# ecd5_target_db register map
Vendor: Texas Instruments
Address unit: 16 bits
Registers are 32-bit, access per field, reset 0x0 unless marked. A register's access mark holds for its fields unless they carry their own. Offsets are as the file gives them; [hi:lo] are bit positions; {n}, {i} and the like mark numbered series; 'fields as' and 'values as' point back to an identical list.

## DSS (part 4 of 5) — ipxact12_to_ccs_generated
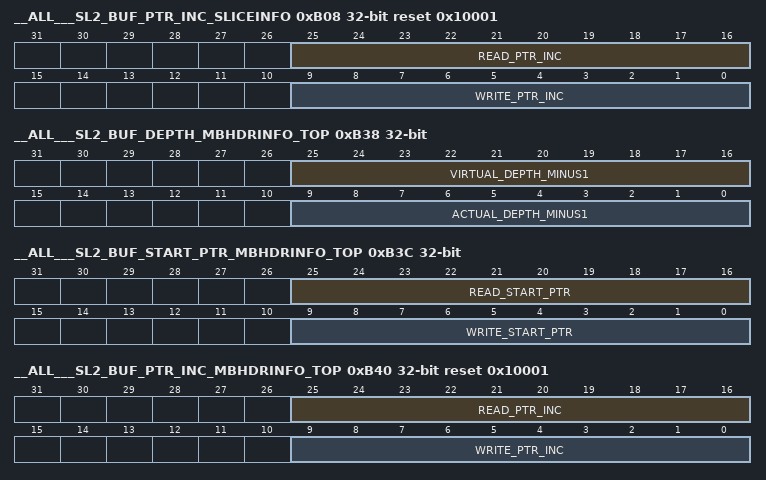
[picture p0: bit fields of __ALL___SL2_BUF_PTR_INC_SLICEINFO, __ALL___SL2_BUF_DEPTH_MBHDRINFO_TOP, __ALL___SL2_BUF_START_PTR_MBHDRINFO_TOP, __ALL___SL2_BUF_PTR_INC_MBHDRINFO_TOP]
0xB08 __ALL___SL2_BUF_PTR_INC_SLICEINFO reset 0x10001 — Buffer Control Pointer Increment Parameters for sliceInfo Note : 1. In decode, in CABAC N MB decoupled mode, this register defines the read and write pointer increment values for the sliceInfo SL2BC between FE and BE (input to BE from FE) 2. In decode, in frame decoupled mode and CAVLC mode, this register defines the write pointer increment value for the sliceInfo SL2BC between the BE and the ROP (output from BE to ROP) 3. In encode, this register defines the read and write pointer increment values for the sliceInfo SL2BC between ROP and BE (input to BE from ROP)
  [25:16] READ_PTR_INC rw — BC Increment value for read pointer
  [9:0] WRITE_PTR_INC rw — BC Increment value for Write pointer
0xB0C __ALL___SL2_BUF_DEPTH_MB — Buffer Control Parameters for MB virtual buffer between FE and BE Note : Valid only in CABAC N MB decoupled mode.
  [9:0] ACTUAL_DEPTH_MINUS1 rw — BC Actual Depth
{0xB18+8i} __ALL___SL2_BUF_DEPTH_BIN{i} (i=0..3) — Buffer Control Parameters for bin stream {i} Note : Valid only in N MB decoupled mode
  [15:0] ACTUAL_DEPTH_MINUS1 rw — BC Actual Depth
{0xB1C+8i} __ALL___SL2_BUF_START_PTR_BIN{i} (i=0..3) — Buffer Control Pointers for bit stream {i} Note : Valid only in N MB decoupled mode
  [9:0] READ_START_PTR rw — BC Start Value for Read Pointer
0xB38 __ALL___SL2_BUF_DEPTH_MBHDRINFO_TOP — Buffer Control Parameters for Top MBHdrInfo in decode, and Top/Bottom in Encode (both top and bottom MBHdrInfo go into the same buffer in encode)
  [25:16] VIRTUAL_DEPTH_MINUS1 rw — BC Virtual Depth
  [9:0] ACTUAL_DEPTH_MINUS1 rw — BC Actual Depth
0xB3C __ALL___SL2_BUF_START_PTR_MBHDRINFO_TOP — Buffer Control Pointers for Top MBHdrInfo in decode, and Top/Bottom in Encode (both top and bottom MBHdrInfo go into the same buffer in encode)
  [25:16] READ_START_PTR rw — BC Start Value for Read Pointer
  [9:0] WRITE_START_PTR rw — BC Start Value for Write Pointer
0xB40 __ALL___SL2_BUF_PTR_INC_MBHDRINFO_TOP reset 0x10001 — Buffer Control Pointer Increment Parameters for Top MBHdrInfo in decode, and Top/Bottom in Encode (both top and bottom MBHdrInfo go into the same buffer in encode)
  fields as __ALL___SL2_BUF_PTR_INC_SLICEINFO
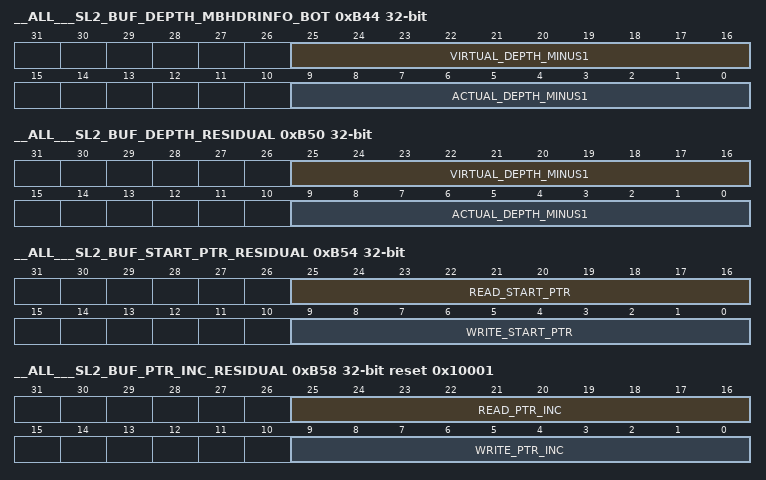
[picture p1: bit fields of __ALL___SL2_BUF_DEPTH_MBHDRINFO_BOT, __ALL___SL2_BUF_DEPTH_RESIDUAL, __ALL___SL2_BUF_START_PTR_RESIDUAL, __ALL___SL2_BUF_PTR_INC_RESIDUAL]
0xB44 __ALL___SL2_BUF_DEPTH_MBHDRINFO_BOT — Buffer Control Parameters for Bottom MBHdrInfo in decode Note : Unused in encode
  fields as __ALL___SL2_BUF_DEPTH_MBHDRINFO_TOP
0xB48 __ALL___SL2_BUF_START_PTR_MBHDRINFO_BOT — Buffer Control Pointers for Bottom MBHdrInfo in decode Note : Unused in encode
  [9:0] WRITE_START_PTR rw — BC Start Value for Write Pointer
0xB4C __ALL___SL2_BUF_PTR_INC_MBHDRINFO_BOT reset 0x1 — Buffer Control Pointer Increment Parameters for Bottom MBHdrInfo in decode Note : Unused in encode
  [9:0] WRITE_PTR_INC rw — BC Increment value for Write pointer
0xB50 __ALL___SL2_BUF_DEPTH_RESIDUAL — Buffer Control Parameters for Residual Data Note : Used in both encode and decode
  fields as __ALL___SL2_BUF_DEPTH_MBHDRINFO_TOP
0xB54 __ALL___SL2_BUF_START_PTR_RESIDUAL — Buffer Control Pointers for Residual Data Note : Used in both encode and decode
  fields as __ALL___SL2_BUF_START_PTR_MBHDRINFO_TOP
0xB58 __ALL___SL2_BUF_PTR_INC_RESIDUAL reset 0x10001 — Buffer Control Pointer Increment Parameters for Residual Data Note : Used in both encode and decode
  fields as __ALL___SL2_BUF_PTR_INC_SLICEINFO
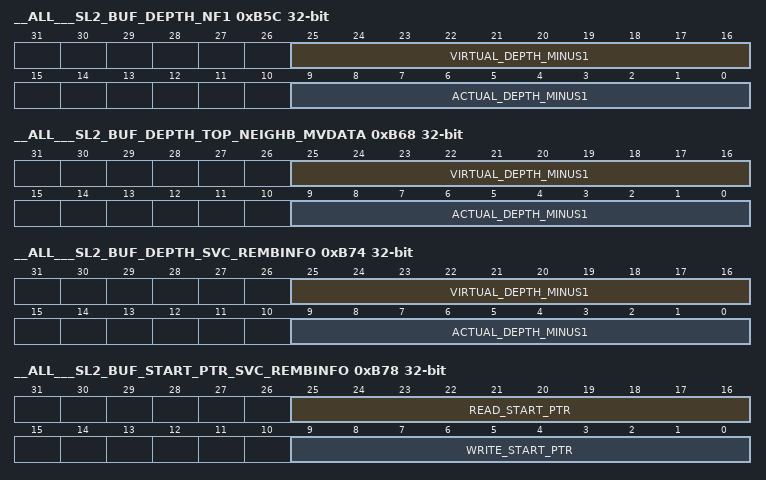
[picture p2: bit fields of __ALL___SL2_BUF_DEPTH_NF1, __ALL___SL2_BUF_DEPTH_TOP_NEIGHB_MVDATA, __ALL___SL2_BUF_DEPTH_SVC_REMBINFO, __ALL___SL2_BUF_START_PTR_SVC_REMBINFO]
0xB5C __ALL___SL2_BUF_DEPTH_NF1 — Buffer Control Parameters for NearNeighbourFlag (NF1) Note : Used in both encode and decode
  fields as __ALL___SL2_BUF_DEPTH_MBHDRINFO_TOP
0xB60 __ALL___SL2_BUF_START_PTR_NF1 — Buffer Control Pointers for NearNeighbourFlag (NF1) Note : Used in both encode and decode
  [9:0] WRITE_START_PTR rw — BC Start Value for Write Pointer
0xB64 __ALL___SL2_BUF_PTR_INC_NF1 reset 0x1 — Buffer Control Pointer Increment Parameters for NearNeighbourFlag (NF1) Note : Used in both encode and decode
  [9:0] WRITE_PTR_INC rw — BC Increment value for Write pointer
0xB68 __ALL___SL2_BUF_DEPTH_TOP_NEIGHB_MVDATA — Buffer Control Parameters for Top Neighbouring MB data to ME This is used only in encode
  fields as __ALL___SL2_BUF_DEPTH_MBHDRINFO_TOP
0xB6C __ALL___SL2_BUF_START_PTR_TOP_NEIGHB_MVDATA — Buffer Control Pointers for Top Neighbouring MB data to ME This is used only in encode
  [9:0] WRITE_START_PTR rw — BC Start Value for Write Pointer
0xB70 __ALL___SL2_BUF_PTR_INC_TOP_NEIGHB_MVDATA reset 0x1 — Buffer Control Pointer Increment Parameters for Top Neighbouring MB data to ME This is used only in encode
  [9:0] WRITE_PTR_INC rw — BC Increment value for Write pointer
0xB74 __ALL___SL2_BUF_DEPTH_SVC_REMBINFO — Buffer Control Parameters for SVC Reference Layer ECD MB Info
  fields as __ALL___SL2_BUF_DEPTH_MBHDRINFO_TOP
0xB78 __ALL___SL2_BUF_START_PTR_SVC_REMBINFO — Buffer Control Pointers for SVC Reference Layer ECD MB Info
  fields as __ALL___SL2_BUF_START_PTR_MBHDRINFO_TOP
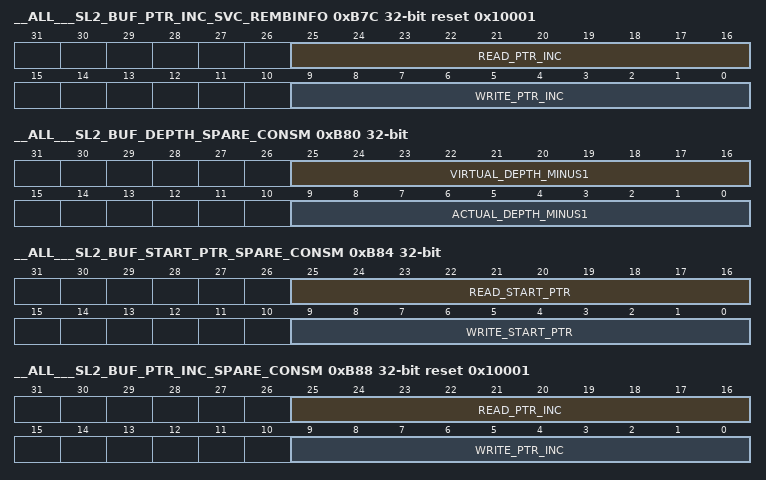
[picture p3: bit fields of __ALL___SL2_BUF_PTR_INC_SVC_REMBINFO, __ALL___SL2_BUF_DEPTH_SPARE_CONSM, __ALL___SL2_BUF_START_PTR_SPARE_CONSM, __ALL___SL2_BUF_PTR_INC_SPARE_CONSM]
0xB7C __ALL___SL2_BUF_PTR_INC_SVC_REMBINFO reset 0x10001 — Buffer Control Pointer Increment Parameters for SVC Reference Layer ECD MB Info
  fields as __ALL___SL2_BUF_PTR_INC_SLICEINFO
0xB80 __ALL___SL2_BUF_DEPTH_SPARE_CONSM — Buffer Control Parameters for Spare Consumer SL2BC
  fields as __ALL___SL2_BUF_DEPTH_MBHDRINFO_TOP
0xB84 __ALL___SL2_BUF_START_PTR_SPARE_CONSM — Buffer Control Pointers for Spare Consumer SL2BC
  fields as __ALL___SL2_BUF_START_PTR_MBHDRINFO_TOP
0xB88 __ALL___SL2_BUF_PTR_INC_SPARE_CONSM reset 0x10001 — Buffer Control Pointer Increment Parameters for Spare Consumer SL2BC
  fields as __ALL___SL2_BUF_PTR_INC_SLICEINFO
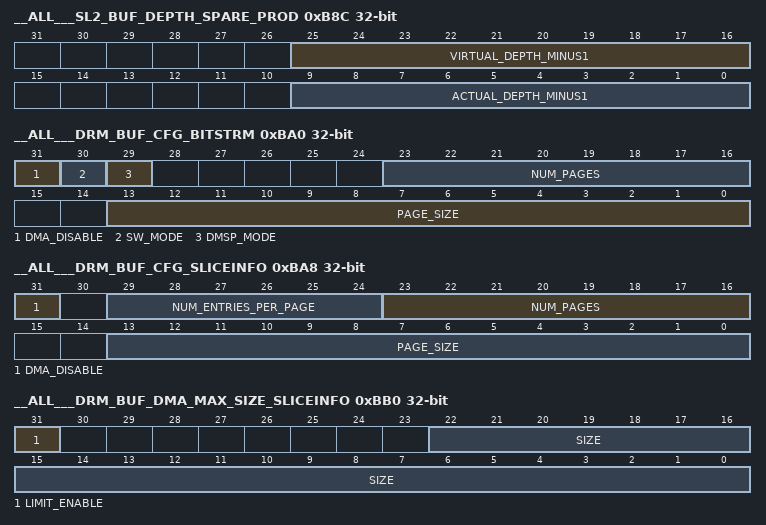
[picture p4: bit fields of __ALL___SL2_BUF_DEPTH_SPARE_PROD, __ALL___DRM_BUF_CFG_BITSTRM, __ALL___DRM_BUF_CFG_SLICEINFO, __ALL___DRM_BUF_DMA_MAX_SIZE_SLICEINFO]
0xB8C __ALL___SL2_BUF_DEPTH_SPARE_PROD — Buffer Control Parameters for Spare Producer SL2BC
  fields as __ALL___SL2_BUF_DEPTH_MBHDRINFO_TOP
0xB90 __ALL___SL2_BUF_START_PTR_SPARE_PROD — Buffer Control Pointers for Spare Producer SL2BC
  [9:0] WRITE_START_PTR rw — BC Start Value for Write Pointer
0xB94 __ALL___SL2_BUF_PTR_INC_SPARE_PROD reset 0x1 — Buffer Control Pointer Increment Parameters for Spare Priducer SL2BC
  [9:0] WRITE_PTR_INC rw — BC Increment value for Write pointer
0xBA0 __ALL___DRM_BUF_CFG_BITSTRM — Buffer parameters and configuration for bit stream Note : Unused in non-frame-decoupled configuration; the corresponding registers in FE_BUFFER_CONTROL are used.
  [31] DMA_DISABLE rw — If '1', disables the triggering of VDMA. Only the SL2 buffer management is activated.
  [30] SW_MODE rw — If '1', specifies SW interactive mode of operation. In this mode, the ECD5 does not interact directly with VDMA for bitstream DMA. Instead it triggers an interrupt for requesting DMA transfer of bitstream.
  [29] DMSP_MODE rw — If '1', specifies "Direct Multi-page SL2 population" mode of operation
  [23:16] NUM_PAGES rw — Number of pages in SL2
  [13:0] PAGE_SIZE rw — Size of each page in SL2 (in bytes); bits[3:0] are ignored, so the effective size is a multiple of 16 bytes
0xBA4 __ALL___DRM_BUF_DMAGROUPID_BITSTRM — DMA Group ID for bit stream Note : Unused in non-frame-decoupled configuration; the corresponding registers in FE_BUFFER_CONTROL are used.
  [5:0] ID rw — Group ID for VDMA transfer
0xBA8 __ALL___DRM_BUF_CFG_SLICEINFO — Buffer parameters and configuration for sliceInfo and sliceRPL Note : Used only in frame decoupled mode
  [31] DMA_DISABLE rw — If '1', disables the triggering of VDMA. Only the SL2 buffer management is activated.
  [29:24] NUM_ENTRIES_PER_PAGE rw — Number of data structure entries in each page of sliceInfo, sliceExpWeightTable and sliceRPL data. Note : This field (together w/ the size of each entry, i.e. for eg. sliceInfo size (2 words)) should be consistent with the PAGE_SIZE field, i.e. NUM_PAGE_ENTRIES * sizeof(sliceInfo) = DRM_BUF_CFG_SLICEINFO.PAGE_SIZE
  [23:16] NUM_PAGES rw — Number of pages of sliceInfo in SL2
  [13:0] PAGE_SIZE rw — Size of each page of sliceInfo in SL2 (in bytes); bits[3:0] are ignored, so the effective size is a multiple of 16 bytes This should be consistent w/ the value of DRM_BUF_CFG_SLICEINFO.NUM_ENTRIES_PER_PAGE, such that this number of sliceInfo entries should fit within the page size.
0xBAC __ALL___DRM_BUF_DMAGROUPID_SLICEINFO — DMA Group ID for sliceInfo and sliceRPL Note : Used only in frame decoupled mode
  [5:0] ID rw — Group ID for VDMA transfer
0xBB0 __ALL___DRM_BUF_DMA_MAX_SIZE_SLICEINFO — Max bytes DMA transfer limit for sliceRPL Note : Used only in frame decoupled mode
  [31] LIMIT_ENABLE rw — If '1', enables limiting the DMA transfer for bin stream 0 to "SIZE"
  [22:0] SIZE rw — Total maximum number of bytes that will be transferred by ECD through VDMA. The actual limit for transfer is "ceil( SIZE / DRM_BUF_CFG_SLICEINFO.PAGE_SIZE ) * PAGE_SIZE", i.e. the closest upper integral number of pages. This value will be decremented by HW when DRM is operational and should not be overwritten except when DRM is in IDLE.
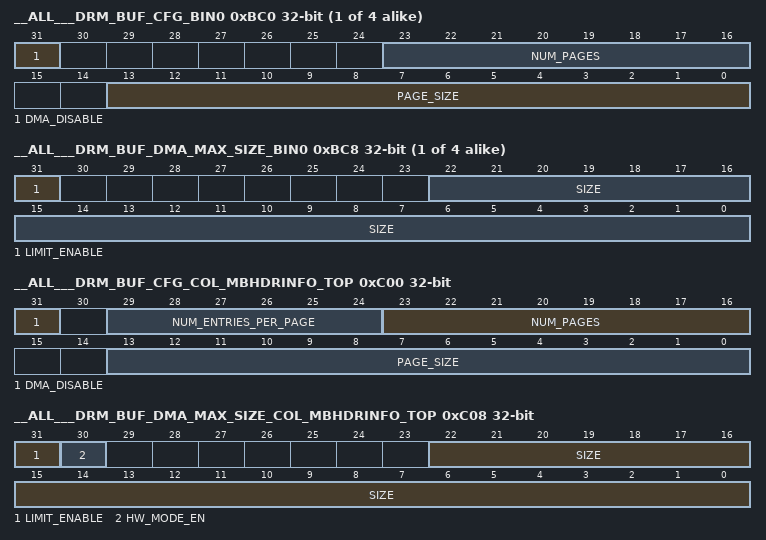
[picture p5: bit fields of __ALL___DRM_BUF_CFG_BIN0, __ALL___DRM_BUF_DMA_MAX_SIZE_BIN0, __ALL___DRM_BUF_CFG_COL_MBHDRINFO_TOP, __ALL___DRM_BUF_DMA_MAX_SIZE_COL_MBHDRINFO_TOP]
{0xBC0+0x10*i} __ALL___DRM_BUF_CFG_BIN{i} (i=0..3) — Buffer parameters and configuration for bin stream {i} Note : Used only in frame decoupled mode
  [31] DMA_DISABLE rw — If '1', disables the triggering of VDMA. Only the SL2 buffer management is activated.
  [23:16] NUM_PAGES rw — Number of pages in SL2
  [13:0] PAGE_SIZE rw — Size of each page in SL2 (in bytes); bits[3:0] are ignored, so the effective size is a multiple of 16 bytes
{0xBC4+0x10*i} __ALL___DRM_BUF_DMAGROUPID_BIN{i} (i=0..3) — DMA Group ID for bin stream {i} Note : Used only in frame decoupled mode
  [5:0] ID rw — Group ID for VDMA transfer
{0xBC8+0x10*i} __ALL___DRM_BUF_DMA_MAX_SIZE_BIN{i} (i=0..3) — Max bytes DMA transfer limit for bin stream {i} Note : Used only in frame decoupled mode
  [31] LIMIT_ENABLE rw — If '1', enables limiting the DMA transfer for bin stream 0 to "SIZE"
  [22:0] SIZE rw — Total maximum number of bytes that will be transferred by ECD through VDMA. The actual limit for transfer is "ceil( SIZE / DRM_BUF_CFG_BIN{i}.PAGE_SIZE ) * PAGE_SIZE", i.e. the closest upper integral number of pages. This value will be decremented by HW when DRM is operational and should not be overwritten except when DRM is in IDLE.
0xC00 __ALL___DRM_BUF_CFG_COL_MBHDRINFO_TOP — Buffer parameters and configuration for colocated Top MBHdrInfo
  [31] DMA_DISABLE rw — If '1', disables the triggering of VDMA. Only the SL2 buffer management is activated.
  [29:24] NUM_ENTRIES_PER_PAGE rw — Number of data structure entries in each page Note : This field (together w/ the size of each entry) should be consistent with the PAGE_SIZE field
  [23:16] NUM_PAGES rw — Number of pages in SL2
  [13:0] PAGE_SIZE rw — Size of each page in SL2 (in bytes); bits[3:0] are ignored, so the effective size is a multiple of 16 bytes Note : Can be left unused since deterministic transfer
0xC04 __ALL___DRM_BUF_DMAGROUPID_COL_MBHDRINFO_TOP — DMA Group ID for colocated Top MBHdrInfo
  [5:0] ID rw — Group ID for VDMA transfer
0xC08 __ALL___DRM_BUF_DMA_MAX_SIZE_COL_MBHDRINFO_TOP — Max bytes DMA transfer limit for colocated Top MBHdrInfo
  [31] LIMIT_ENABLE rw — If '1', enables limiting the DMA transfer for bin stream 0 to "SIZE"
  [30] HW_MODE_EN rw — If "1" enables programmation of the "SIZE" field through H/W interface
  [22:0] SIZE rw — Total maximum number of bytes that will be transferred by ECD through VDMA. The actual limit for transfer is "ceil( SIZE / DRM_BUF_CFG_COL_MBHDRINFO_TOP.PAGE_SIZE ) * PAGE_SIZE", i.e. the closest upper integral number of pages. This value will be decremented by HW when DRM is operational and should not be overwritten except when DRM is in IDLE.
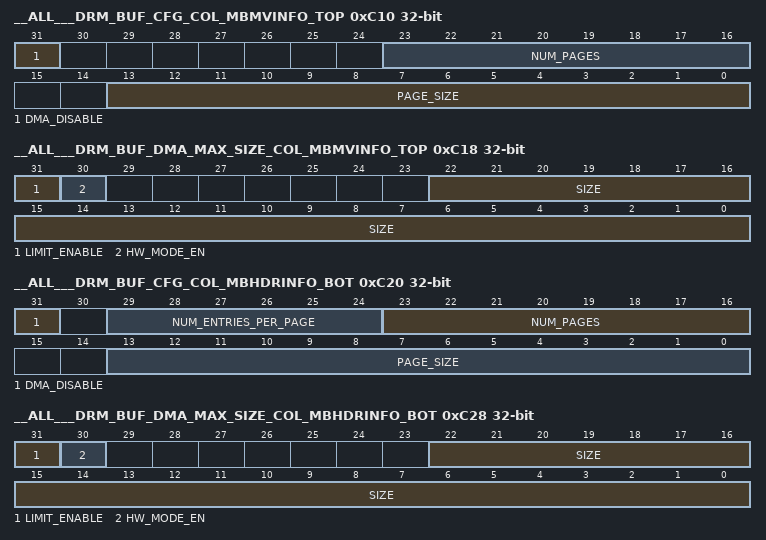
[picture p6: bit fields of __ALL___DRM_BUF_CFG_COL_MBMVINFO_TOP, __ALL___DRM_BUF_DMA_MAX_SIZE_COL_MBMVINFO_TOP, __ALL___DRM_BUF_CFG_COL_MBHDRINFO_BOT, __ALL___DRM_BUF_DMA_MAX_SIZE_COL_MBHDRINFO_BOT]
0xC10 __ALL___DRM_BUF_CFG_COL_MBMVINFO_TOP — Buffer parameters and configuration for colocated Top MBMVInfo
  fields as __ALL___DRM_BUF_CFG_BIN0
0xC14 __ALL___DRM_BUF_DMAGROUPID_COL_MBMVINFO_TOP — DMA Group ID for colocated Top MBMVInfo
  [5:0] ID rw — Group ID for VDMA transfer
0xC18 __ALL___DRM_BUF_DMA_MAX_SIZE_COL_MBMVINFO_TOP — Max bytes DMA transfer limit for colocated Top MBMVInfo
  [31] LIMIT_ENABLE rw — If '1', enables limiting the DMA transfer for bin stream 0 to "SIZE"
  [30] HW_MODE_EN rw — If "1" enables programmation of the "SIZE" field through H/W interface
  [22:0] SIZE rw — Total maximum number of bytes that will be transferred by ECD through VDMA. The actual limit for transfer is "ceil( SIZE / DRM_BUF_CFG_COL_MBMVINFO_TOP.PAGE_SIZE ) * PAGE_SIZE", i.e. the closest upper integral number of pages. This value will be decremented by HW when DRM is operational and should not be overwritten except when DRM is in IDLE.
0xC20 __ALL___DRM_BUF_CFG_COL_MBHDRINFO_BOT — Buffer parameters and configuration for colocated Bottom MBHdrInfo
  [31] DMA_DISABLE rw — If '1', disables the triggering of VDMA. Only the SL2 buffer management is activated.
  [29:24] NUM_ENTRIES_PER_PAGE rw — Number of data structure entries in each page Note : This field (together w/ the size of each entry) should be consistent with the PAGE_SIZE field
  [23:16] NUM_PAGES rw — Number of pages in SL2
  [13:0] PAGE_SIZE rw — Size of each page in SL2 (in bytes); bits[3:0] are ignored, so the effective size is a multiple of 16 bytes
0xC24 __ALL___DRM_BUF_DMAGROUPID_COL_MBHDRINFO_BOT — DMA Group ID for colocated Bottom MBHdrInfo
  [5:0] ID rw — Group ID for VDMA transfer
0xC28 __ALL___DRM_BUF_DMA_MAX_SIZE_COL_MBHDRINFO_BOT — Max bytes DMA transfer limit for colocated Bottom MBHdrInfo
  [31] LIMIT_ENABLE rw — If '1', enables limiting the DMA transfer for bin stream 0 to "SIZE"
  [30] HW_MODE_EN rw — If "1" enables programmation of the "SIZE" field through H/W interface
  [22:0] SIZE rw — Total maximum number of bytes that will be transferred by ECD through VDMA. The actual limit for transfer is "ceil( SIZE / DRM_BUF_CFG_COL_MBHDRINFO_BOT.PAGE_SIZE ) * PAGE_SIZE", i.e. the closest upper integral number of pages. This value will be decremented by HW when DRM is operational and should not be overwritten except when DRM is in IDLE.
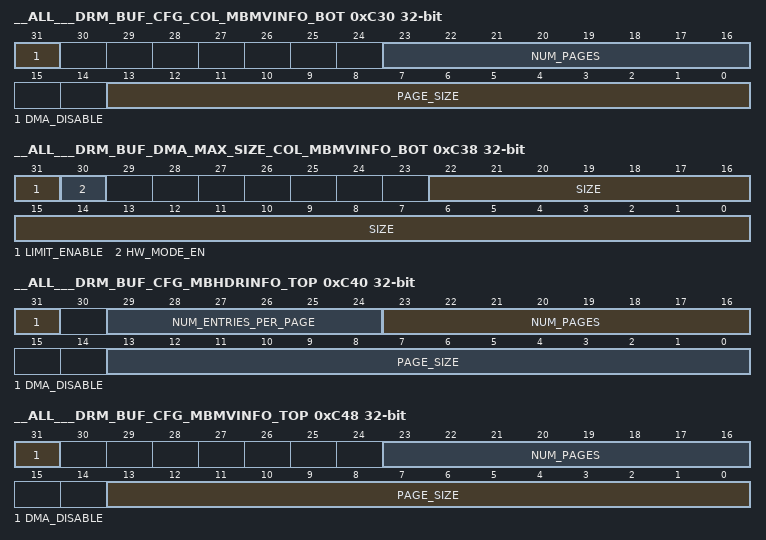
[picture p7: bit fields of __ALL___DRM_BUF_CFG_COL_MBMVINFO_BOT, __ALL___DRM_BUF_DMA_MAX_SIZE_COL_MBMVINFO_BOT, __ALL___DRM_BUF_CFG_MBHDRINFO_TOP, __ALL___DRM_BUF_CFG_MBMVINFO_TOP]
0xC30 __ALL___DRM_BUF_CFG_COL_MBMVINFO_BOT — Buffer parameters and configuration for colocated Bottom MBMVInfo
  fields as __ALL___DRM_BUF_CFG_BIN0
0xC34 __ALL___DRM_BUF_DMAGROUPID_COL_MBMVINFO_BOT — DMA Group ID for colocated Bottom MBMVInfo
  [5:0] ID rw — Group ID for VDMA transfer
0xC38 __ALL___DRM_BUF_DMA_MAX_SIZE_COL_MBMVINFO_BOT — Max bytes DMA transfer limit for colocated Bottom MBMVInfo
  [31] LIMIT_ENABLE rw — If '1', enables limiting the DMA transfer for bin stream 0 to "SIZE"
  [30] HW_MODE_EN rw — If "1" enables programmation of the "SIZE" field through H/W interface
  [22:0] SIZE rw — Total maximum number of bytes that will be transferred by ECD through VDMA. The actual limit for transfer is "ceil( SIZE / DRM_BUF_CFG_COL_MBMVINFO_BOT.PAGE_SIZE ) * PAGE_SIZE", i.e. the closest upper integral number of pages. This value will be decremented by HW when DRM is operational and should not be overwritten except when DRM is in IDLE.
0xC40 __ALL___DRM_BUF_CFG_MBHDRINFO_TOP — Buffer parameters and configuration for current Top MBHdrInfo
  fields as __ALL___DRM_BUF_CFG_COL_MBHDRINFO_BOT
0xC44 __ALL___DRM_BUF_DMAGROUPID_MBHDRINFO_TOP — DMA Group ID for current Top MBHdrInfo
  [5:0] ID rw — Group ID for VDMA transfer
0xC48 __ALL___DRM_BUF_CFG_MBMVINFO_TOP — Buffer parameters and configuration for current Top MBMVInfo
  fields as __ALL___DRM_BUF_CFG_BIN0
0xC4C __ALL___DRM_BUF_DMAGROUPID_MBMVINFO_TOP — DMA Group ID for current Top MBMVInfo
  [5:0] ID rw — Group ID for VDMA transfer
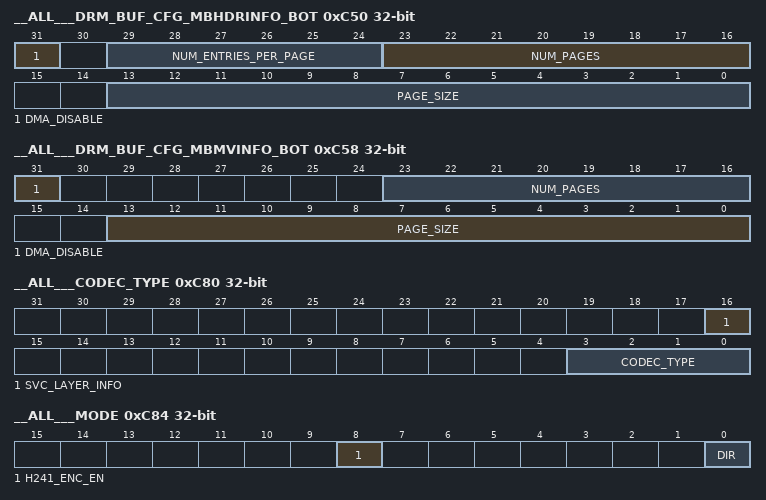
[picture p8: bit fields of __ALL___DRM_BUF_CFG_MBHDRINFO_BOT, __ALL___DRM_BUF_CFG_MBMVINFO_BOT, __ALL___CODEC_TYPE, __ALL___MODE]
0xC50 __ALL___DRM_BUF_CFG_MBHDRINFO_BOT — Buffer parameters and configuration for current Bottom MBHdrInfo
  fields as __ALL___DRM_BUF_CFG_COL_MBHDRINFO_BOT
0xC54 __ALL___DRM_BUF_DMAGROUPID_MBHDRINFO_BOT — DMA Group ID for current Bottom MBHdrInfo
  [5:0] ID rw — Group ID for VDMA transfer
0xC58 __ALL___DRM_BUF_CFG_MBMVINFO_BOT — Buffer parameters and configuration for current Bottom MBMVInfo
  fields as __ALL___DRM_BUF_CFG_BIN0
0xC5C __ALL___DRM_BUF_DMAGROUPID_MBMVINFO_BOT — DMA Group ID for current Bottom MBMVInfo
  [5:0] ID rw — Group ID for VDMA transfer
0xC80 __ALL___CODEC_TYPE — Codec Type
  [16] SVC_LAYER_INFO rw — Specifies whether current layer is base or enhancement layer; valid only id CODEC_TYPE == 1 (SVC) 0 - Base Layer 1 - Enhancement Layer
  [3:0] CODEC_TYPE rw — 0=>H.264, 1=>SVC, 2=>VP8
0xC84 __ALL___MODE — BE Mode
  [8] H241_ENC_EN rw — Specifies if Encoder is in H.241 mode 0 - H.241 Mode disabled 1 - H.241 Mode enabled
  [0] DIR rw — Specifies if encode or decode for BE 0 - Decode 1 - Encode Note : If DIR == 1 and ENTROPY_CODING_MODE == 1, note that FE0 shall not be enabled (since CABAC engine 0 will be used in encode mode)
0xC90 __ALL___DEC_CABAC_FRM_CFG ro — Frame Level Config for CABAC in decode
0xC94 __ALL___DEC_CABAC_L0_CFG ro — CABAC Basic (Level 0) Config for decode
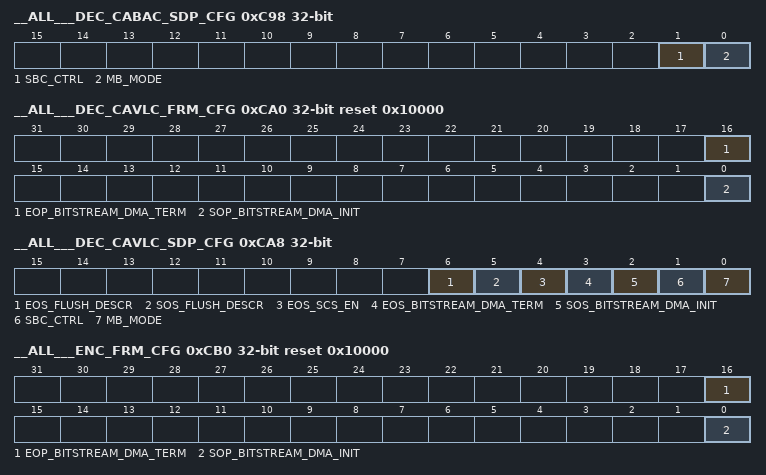
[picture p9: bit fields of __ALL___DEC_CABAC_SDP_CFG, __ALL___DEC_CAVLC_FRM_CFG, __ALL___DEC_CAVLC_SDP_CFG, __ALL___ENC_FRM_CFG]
0xC98 __ALL___DEC_CABAC_SDP_CFG — CABAC Slice Data Decode Configuration register
  [1] SBC_CTRL rw — Specifies the bin SBC control mode 0 - Initialize and Flush SBC at beginning and end of pipe respectively 1 - Initialize and Flush SBC at beginning and end of every MB respectively
  [0] MB_MODE rw — Specifies if MB mode is enabled for slice data decode 0 - No control at MB level 1 - MB processing engine has to be specifically enabled at every MB
0xCA0 __ALL___DEC_CAVLC_FRM_CFG reset 0x10000 — Frame Level Config for CAVLC in decode
  [16] EOP_BITSTREAM_DMA_TERM rw — Specifies if bit-stream DMA needs to be terminated at the end of pipe 0 - Do not terminate bit stream DMA at the end of pipe 1 - Terminate bitstream DMA at end of pipe
  [0] SOP_BITSTREAM_DMA_INIT rw — Specifies if bit-stream DMA needs to be initialized at the start of pipe (frame/sub-frame) 0 - Disable 1 - Enable
0xCA4 __ALL___DEC_CAVLC_L0_CFG ro — CAVLC Basic (Level 0) Config for decode
0xCA8 __ALL___DEC_CAVLC_SDP_CFG — CAVLC Decode Slice Data Processing Configuration
  [6] EOS_FLUSH_DESCR rw — Enable/Disable flush of current bitstream descriptor at end of slice 0 - Disable 1 - Enable
  [5] SOS_FLUSH_DESCR rw — Enable/Disable flush of current bitstream descriptor at start of slice 0 - Disable 1 - Enable
  [4] EOS_SCS_EN rw — Enable/Disable automatic startcode search on detecting end of slice 0 - Disable 1 - Enable
  [3] EOS_BITSTREAM_DMA_TERM rw — Specifies if bit-stream DMA needs to be terminated at the end of slice 0 - Do not terminate bit stream DMA at the end of slice 1 - Terminate bitstream DMA at end of slice
  [2] SOS_BITSTREAM_DMA_INIT rw — Specifies if bit-stream DMA need to be init at beginning of slice data processing 0 - Do not trigger initial bit stream DMA at the beginning of slice 1 - Trigger bitstream DMA at beginning of every slice
  [1] SBC_CTRL rw — Specifies the SBC control mode 0 - Initialize and Flush SBC at beginning and end of slice respectively 1 - Initialize and Flush SBC at beginning and end of every MB respectively Note : If SDP_EOS_SCS_EN == 1, then this bit will take effect for SBC close after the startcode search after EOS.
  [0] MB_MODE rw — Specifies if MB mode is enabled for slice data decode 0 - No control at MB level 1 - MB processing engine has to be specifically enabled at every MB
0xCB0 __ALL___ENC_FRM_CFG reset 0x10000 — Encoder Frame Level Initialization Configuration
  [16] EOP_BITSTREAM_DMA_TERM rw — Specifies if bit-stream DMA needs to be terminated at the end of pipe 0 - Do not terminate bit stream DMA at the end of pipe 1 - Terminate bitstream DMA at end of pipe Setting this bit results in flushing any un-transferred bit-stream data in the SL2 to DDR at the end of pipe, and discarding of bit-stream descriptors.
  [0] SOP_BITSTREAM_DMA_INIT rw — Specifies if bit-stream DMA needs to be initialized at the start of pipe (frame/sub-frame) 0 - Disable 1 - Enable
0xCB4 __ALL___ENC_L0_CFG ro — Encoder Basic (Level 0) Configuration
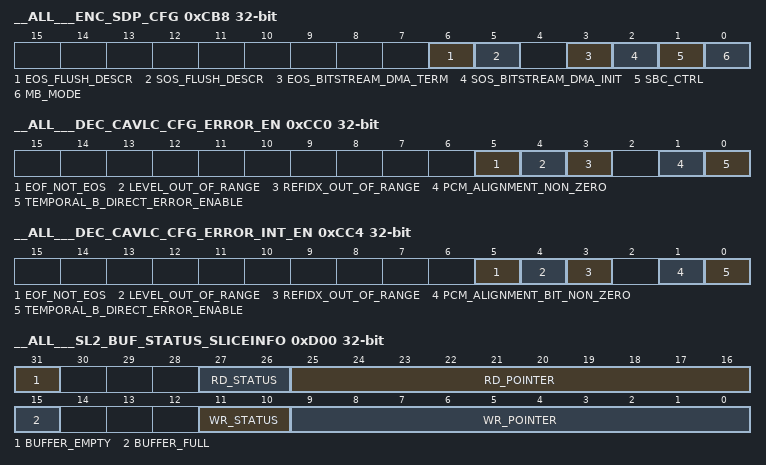
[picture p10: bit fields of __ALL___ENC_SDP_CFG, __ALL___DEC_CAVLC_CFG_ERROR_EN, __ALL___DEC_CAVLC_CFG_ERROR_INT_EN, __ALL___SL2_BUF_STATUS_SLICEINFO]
0xCB8 __ALL___ENC_SDP_CFG — Encoder Slice Processing Configuration
  [6] EOS_FLUSH_DESCR rw — Enable/Disable flush of current bitstream descriptor at end of slice 0 - Disable 1 - Enable
  [5] SOS_FLUSH_DESCR rw — Enable/Disable flush of current bitstream descriptor at start of slice 0 - Disable 1 - Enable
  [3] EOS_BITSTREAM_DMA_TERM rw — Specifies if bit-stream DMA needs to be terminated at the end of slice 0 - Do not terminate bit stream DMA at the end of slice 1 - Terminate bitstream DMA at end of slice Setting this bit results in flushing any un-transferred bit-stream data in the SL2 to DDR at the end of slice, and discarding of the bit-stream descriptors
  [2] SOS_BITSTREAM_DMA_INIT rw — Specifies if bit-stream DMA need to be init at beginning of slice data processing 0 - Do not initialize bit stream DMA at the beginning of slice 1 - Initialize bitstream DMA at beginning of every slice
  [1] SBC_CTRL rw — Specifies the SBC control mode 0 - Initialize and Flush SBC at beginning and end of slice respectively 1 - Initialize and Flush SBC at beginning and end of every MB respectively
  [0] MB_MODE rw — Specifies if MB mode is enabled for slice data decode 0 - No control at MB level 1 - MB processing engine has to be specifically enabled at every MB
0xCC0 __ALL___DEC_CAVLC_CFG_ERROR_EN — CAVLC Configuration register for enabling error for potentially incorrect behavior
  [5] EOF_NOT_EOS rw — If this value is 1 and EOS is not detected while decoding the last MB in the frame, error is flagged immediately.
  [4] LEVEL_OUT_OF_RANGE rw — If this value is 1 and level becomes out of range [-2^(7+bitDepth), 2^(7+bitDepth)-1] (due to error in level_suffix), error is flagged immediately.
  [3] REFIDX_OUT_OF_RANGE rw — If this value is 1 and ref_idx_lx ( x == 0 or 1 ) is out of the range [0,DEC_CAVLC_REF_IDX_MAX_Lx.VALUE], error is flagged immediately .
  [1] PCM_ALIGNMENT_NON_ZERO rw — If this value is 1 and pcm_alignment_zero_bit is not "0", error is flagged immediately.
  [0] TEMPORAL_B_DIRECT_ERROR_ENABLE rw — If this value is 1 and Temporal B Direct MB is detected, error is flagged immediately.
0xCC4 __ALL___DEC_CAVLC_CFG_ERROR_INT_EN — CAVLC Configuration register for enabling interrupt for potential incorrect behavior If a bit is set in this register and corresponding bit is not set in the DEC_CAVLC_CFG_ERROR_EN register, then, on hitting the corresponding condition in an MB, INT_ERR0 is triggered on the completion of the MB. CAVLC_DEC_ERR status bit is set in the interrupt status registers corresponding to INT_ERR0.
  [5] EOF_NOT_EOS rw — If this value is 1 and EOS is not detected while decoding the last MB in the frame, interrupt is (conditionally) generated on completion of MB.
  [4] LEVEL_OUT_OF_RANGE rw — If this value is 1 and level becomes out of range [-2^(7+bitDepth), 2^(7+bitDepth)-1] (due to error in level_suffix), interrupt is (conditionally) generated on completion of MB.
  [3] REFIDX_OUT_OF_RANGE rw — If this value is 1 and ref_idx_lx ( x == 0 or 1 ) is out of the range [0,DEC_CAVLC_REF_IDX_MAX_Lx.VALUE], interrupt is (conditionally) generated on completion of MB.
  [1] PCM_ALIGNMENT_BIT_NON_ZERO rw — If this value is 1 and pcm_alignment_zero_bit is not "0", interrupt is (conditionally) generated on completion of MB.
  [0] TEMPORAL_B_DIRECT_ERROR_ENABLE rw — If this value is 1 and Temporal B Direct MB is detected, interrupt is (conditionally) generated on completion of MB.
0xCC8 __ALL___DEC_CAVLC_REF_IDX_MAX_L0 — CAVLC Max refidx for L0
  [4:0] VALUE rw — Specifies the max refidx value for L0 for error checking
0xCCC __ALL___DEC_CAVLC_REF_IDX_MAX_L1 — CAVLC Max refidx for L1
  [4:0] VALUE rw — Specifies the max refidx value for L1 for error checking
0xCE4 __ALL___BE_MVINFO_TOP_DDR_OFFSET ro (reset mask 0xFF800000) — Start offset for MVInfo top buffer in DDR. Valid only in decode.
0xCE8 __ALL___BE_MVINFO_BOT_DDR_OFFSET ro (reset mask 0xFF800000) — Start offset for MVInfo bottom buffer in DDR. Valid only in decode.
0xD00 __ALL___SL2_BUF_STATUS_SLICEINFO ro — Buffer status for sliceInfo buffer (read/written) by BE Note : 1. Decode - CAVLC mode : this register reflects the status of the sliceInfo buffer between the BE and the ROP (output from BE to ROP). Although the SL2 buffer is not populated by the BE, the BE communicates the availability of data in the buffer to the ROP through SL2BC 2. Decode - CABAC N MB decoupled mode : this register reflects the status for the sliceInfo SL2BC between FE and BE (input to BE from FE) 3. Decode - CABAC frame decoupled mode : this register reflects the status of the sliceInfo buffer between the BE and the ROP (output from BE to ROP) 3. Encode : this register reflects the status for the sliceInfo SL2BC between ROP and BE (input to BE from ROP)
  [31] BUFFER_EMPTY — Buffer Empty Status 0 : Buffer Not Empty 1 : Buffer Empty Valid only in encode and non-frame decoupled CABAC decode
  [27:26] RD_STATUS — Indicates the BC status on the read side BC NOT READY = 00 (rd_core_busy=0 AND rd_bc_ready=0) BC READY = 01 (rd_core_busy=0 AND rd_bc_ready=1) BC BUSY = 1x (rd_core_busy=1) Valid only in encode and non-frame decoupled CABAC decode
  [25:16] RD_POINTER — Current Read Pointer Valid only in encode and non-frame decoupled CABAC decode
  [15] BUFFER_FULL — Buffer Full Status 0 : Buffer Not Full 1 : Buffer Full Valid only in encode and non-frame decoupled CABAC decode
  [11:10] WR_STATUS — Indicates the BC status on the write side BC NOT READY = 00 (wr_core_busy=0 AND wr_bc_ready=0) BC READY = 01 (wr_core_busy=0 AND wr_bc_ready=1) BC BUSY = 1x (wr_core_busy=1)
  [9:0] WR_POINTER — Current Write Pointer
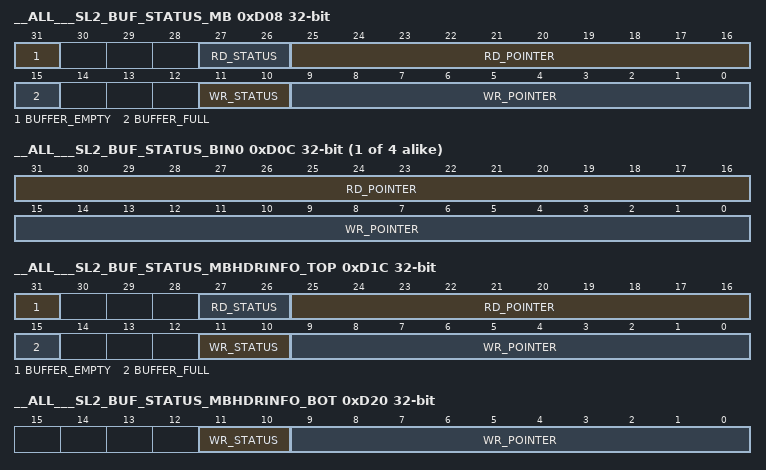
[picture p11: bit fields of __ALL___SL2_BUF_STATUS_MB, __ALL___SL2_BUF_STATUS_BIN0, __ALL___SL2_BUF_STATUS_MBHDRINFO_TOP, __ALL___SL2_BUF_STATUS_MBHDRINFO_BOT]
0xD08 __ALL___SL2_BUF_STATUS_MB ro — Buffer Status for MB virtual buffer between FE and BE Note : Valid only in CABAC decode in N MB decoupled mode
  [31] BUFFER_EMPTY — Buffer Empty Status 0 : Buffer Not Empty 1 : Buffer Empty
  [27:26] RD_STATUS — Indicates the BC status on the read side BC NOT READY = 00 (rd_core_busy=0 AND rd_bc_ready=0) BC READY = 01 (rd_core_busy=0 AND rd_bc_ready=1) BC BUSY = 1x (rd_core_busy=1)
  [25:16] RD_POINTER — Current Read Pointer
  [15] BUFFER_FULL — Buffer Full Status 0 : Buffer Not Full 1 : Buffer Full
  [11:10] WR_STATUS — Indicates the BC status on the write side BC NOT READY = 00 (wr_core_busy=0 AND wr_bc_ready=0) BC READY = 01 (wr_core_busy=0 AND wr_bc_ready=1) BC BUSY = 1x (wr_core_busy=1)
  [9:0] WR_POINTER — Current Write Pointer
{0xD0C+4i} __ALL___SL2_BUF_STATUS_BIN{i} ro (i=0..3) — Buffer Status for bin stream {i} Note : Valid only in CABAC decode in non-frame-decoupled mode
  [31:16] RD_POINTER — Current Read Pointer
  [15:0] WR_POINTER — Current Write Pointer
0xD1C __ALL___SL2_BUF_STATUS_MBHDRINFO_TOP ro — Buffer Status forTop MBHdrInfo in decode, and Top/Bottom in Encode (both top and bottom MBHdrInfo go into the same buffer in encode)
  [31] BUFFER_EMPTY — Buffer Empty Status 0 : Buffer Not Empty 1 : Buffer Empty Note : Valid only in encode
  [27:26] RD_STATUS — Indicates the BC status on the read side BC NOT READY = 00 (rd_core_busy=0 AND rd_bc_ready=0) BC READY = 01 (rd_core_busy=0 AND rd_bc_ready=1) BC BUSY = 1x (rd_core_busy=1) Note : Valid only in encode
  [25:16] RD_POINTER — Current Read Pointer Note : Valid only in encode
  [15] BUFFER_FULL — Buffer Full Status 0 : Buffer Not Full 1 : Buffer Full Note : Valid only in encode
  [11:10] WR_STATUS — Indicates the BC status on the write side BC NOT READY = 00 (wr_core_busy=0 AND wr_bc_ready=0) BC READY = 01 (wr_core_busy=0 AND wr_bc_ready=1) BC BUSY = 1x (wr_core_busy=1)
  [9:0] WR_POINTER — Current Write Pointer
0xD20 __ALL___SL2_BUF_STATUS_MBHDRINFO_BOT ro — Buffer Status for Bottom MBHdrInfo in decode Note :Valid only in decode
  [11:10] WR_STATUS — Indicates the BC status on the write side BC NOT READY = 00 (wr_core_busy=0 AND wr_bc_ready=0) BC READY = 01 (wr_core_busy=0 AND wr_bc_ready=1) BC BUSY = 1x (wr_core_busy=1)
  [9:0] WR_POINTER — Current Write Pointer
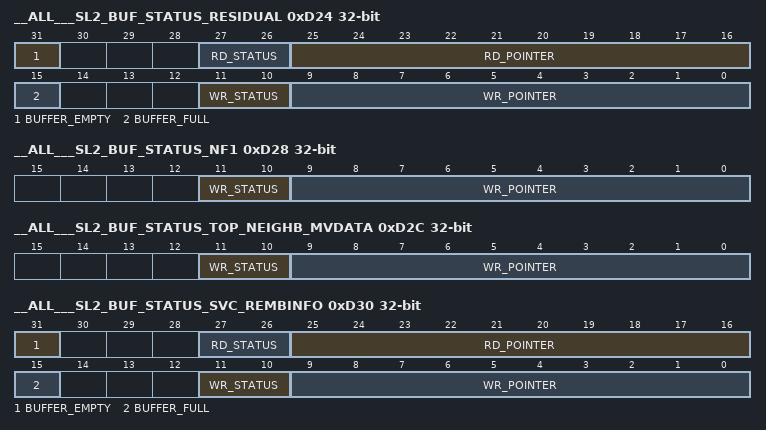
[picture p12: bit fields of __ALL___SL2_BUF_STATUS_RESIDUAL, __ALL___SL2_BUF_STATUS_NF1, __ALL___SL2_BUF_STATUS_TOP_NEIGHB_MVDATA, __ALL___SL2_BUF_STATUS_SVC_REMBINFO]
0xD24 __ALL___SL2_BUF_STATUS_RESIDUAL ro — Buffer Status for Residual Data
  fields as __ALL___SL2_BUF_STATUS_MBHDRINFO_TOP
0xD28 __ALL___SL2_BUF_STATUS_NF1 ro — Buffer Status for NearNeighbourFlag (NF1)
  fields as __ALL___SL2_BUF_STATUS_MBHDRINFO_BOT
0xD2C __ALL___SL2_BUF_STATUS_TOP_NEIGHB_MVDATA ro — Buffer Status for top neighbouring MB data Note : Valid only in encode
  fields as __ALL___SL2_BUF_STATUS_MBHDRINFO_BOT
0xD30 __ALL___SL2_BUF_STATUS_SVC_REMBINFO ro — Buffer Status for SVC Reference Layer ECD MBInfo Note : Valid only in SVC decode
  fields as __ALL___SL2_BUF_STATUS_MB
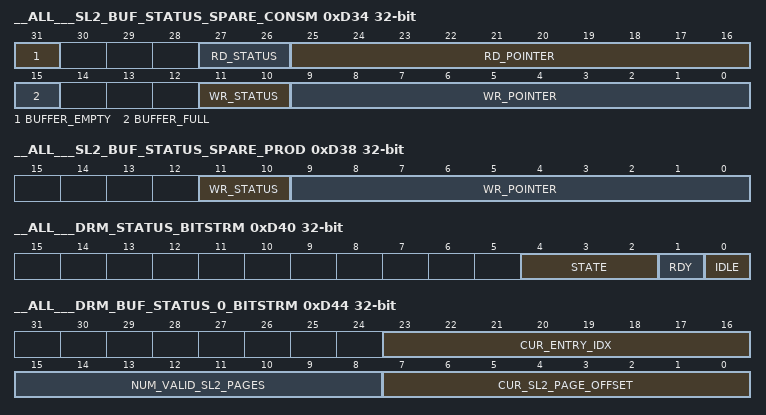
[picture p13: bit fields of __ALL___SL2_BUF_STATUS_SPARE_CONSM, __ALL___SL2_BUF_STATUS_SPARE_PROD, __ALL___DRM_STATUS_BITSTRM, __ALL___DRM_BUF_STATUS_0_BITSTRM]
0xD34 __ALL___SL2_BUF_STATUS_SPARE_CONSM ro — Buffer Status for Spare Consumer SL2BC
  fields as __ALL___SL2_BUF_STATUS_MB
0xD38 __ALL___SL2_BUF_STATUS_SPARE_PROD ro — Buffer Status for Spare producer SL2BC
  fields as __ALL___SL2_BUF_STATUS_MBHDRINFO_BOT
0xD40 __ALL___DRM_STATUS_BITSTRM ro — Status of DRM channel controller for bit stream buffer
  [4:2] STATE — Indicates state of the bitstream control DRM FSM
  [1] RDY — Indicates availability of at least one valid page in SL2 for processing by the ECD core
  [0] IDLE — If "1", indicates that the DRM channel for bitstream control is IDLE. Used to check for completion of DMA after a terminate request.
0xD44 __ALL___DRM_BUF_STATUS_0_BITSTRM ro — Buffer Status for bitstream buffer Valid only in frame decoupled mode Reflects the current internal and DMA status of bit stream buffer
  [23:16] CUR_ENTRY_IDX — Unused
  [15:8] NUM_VALID_SL2_PAGES — Indicates the number of pages currently valid in SL2. In the case of read ( data transferred from DDR to SL2 , and read by the ECD core ), this field indicates the number of pages available for the ECD to read from SL2. This count is initialized to 0 on DRM initialization. This count is incremented on completion of each page of DMA. The count is decremented whenever one page of data is consumed by the ECD core. In the case of write ( data written by ECD core to SL2, and transferred from SL2 to DDR ), this field indicates the number of pages in SL2 available for the ECD core to write into. This count is initialized to the total number of pages (ECD5_BE_BUFFER_CONTROL.DRM_BUF_CFG_[BUFFER_NAME].NUM_PAGES) on DRM initialization. The count is decremented every time ECD writes one page to SL2. The count is incremented whenever the DMA of one page from SL2 to DDR is completed.
  [7:0] CUR_SL2_PAGE_OFFSET — Indicates the SL2 page number where the next data will be read from, by the ECD core (MBP) in decode, or written to , in encode; valid values are 0 to DRM_BUF_PARAMS_[BUFFER_NAME].NUM_PAGES - 1; reset on DMA initialization
0xD48 __ALL___DRM_BUF_STATUS_1_BITSTRM ro — Buffer Status for bit stream buffer Valid only in frame decoupled mode. Reflects the current internal and DMA status of bit stream buffer
  [21:0] CUR_SL2_ADDR — Indicates the SL2 address of the page where the next data will be read from (in decode), or written to (in encode) , by the ECD core (MBP) ; reset on DMA initialization to SL2 base address of the buffer in SL2
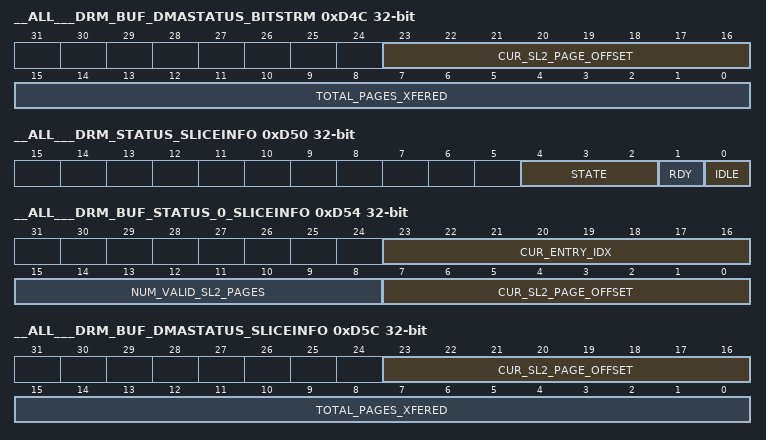
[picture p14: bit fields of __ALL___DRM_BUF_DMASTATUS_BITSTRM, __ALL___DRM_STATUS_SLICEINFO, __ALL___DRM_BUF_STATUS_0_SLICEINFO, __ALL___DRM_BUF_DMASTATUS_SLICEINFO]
0xD4C __ALL___DRM_BUF_DMASTATUS_BITSTRM ro — Buffer DMA Status for bitstream buffer Valid only in frame decoupled mode. Reflects the current DMA status of bin stream 0 buffer
  [23:16] CUR_SL2_PAGE_OFFSET — Indicates the SL2 page number to which the next page DMA will happen (written to) in decode, or from which the next page DMA will happen (read from) in encode, when enabling conditions for DMA are met (SL2 page is consumed by ECD5 core in decode; SL2 page is filled by ECD5 core in encode); valid values are 0 to DRM_BUF_PARAMS_[BUFFER_NAME].NUM_PAGES - 1; reset on DMA initialization
  [15:0] TOTAL_PAGES_XFERED — Indicates the total number of pages for which DMA has completed; reset on DMA initialization
0xD50 __ALL___DRM_STATUS_SLICEINFO ro — Status of DRM channel controller forsliceInfo buffer
  [4:2] STATE — Indicates state of the channel control DRM FSM
  [1] RDY — Indicates availability of at least one valid page in SL2 for processing by the ECD core
  [0] IDLE — If "1", indicates that the DRM channel control FSM is IDLE. Used to check for completion of DMA after a terminate request.
0xD54 __ALL___DRM_BUF_STATUS_0_SLICEINFO ro — Buffer Status for sliceInfo buffer Valid only in frame decoupled mode. Reflects the current internal and DMA status of the buffer
  [23:16] CUR_ENTRY_IDX — For debug only. Indicates the index of the entry that is currently being read or will be read next by the ECD5 core in the current page; reset on DMA initialization
  [15:8] NUM_VALID_SL2_PAGES — Indicates the number of pages currently valid in SL2. This field indicates the number of pages available for the ECD to read from SL2. This count is initialized to 0 on DRM initialization.This count is incremented on completion of each page of DMA. The count is decremented whenever one page of data is consumed by the ECD core.
  [7:0] CUR_SL2_PAGE_OFFSET — Indicates the SL2 page number where the next data will be read from by the ECD core (MBP); valid values are 0 to DRM_BUF_PARAMS_[BUFFER_NAME].NUM_PAGES - 1; reset on DMA initialization
0xD58 __ALL___DRM_BUF_STATUS_1_SLICEINFO ro — Buffer Status for sliceInfo buffer Valid only in frame decoupled mode. Reflects the current internal and DMA status of the buffer
  [21:0] CUR_SL2_ADDR — Indicates the SL2 address of the page where the next data will be read from by the ECD core (MBP) ; reset on DMA initialization to SL2 base address of the buffer in SL2
0xD5C __ALL___DRM_BUF_DMASTATUS_SLICEINFO ro — Buffer DMA Status for sliceInfo buffer Valid only in frame decoupled mode. Reflects the current DMA status of bin stream 3 buffer
  [23:16] CUR_SL2_PAGE_OFFSET — Indicates the SL2 page number to which the next page DMA will happen (written to) when enabling conditions for DMA are met (SL2 page is emptied by ECD5 core); valid values are 0 to DRM_BUF_PARAMS_[BUFFER_NAME].NUM_PAGES - 1; reset on DMA initialization
  [15:0] TOTAL_PAGES_XFERED — Indicates the total number of pages for which DMA has completed; reset on DMA initialization
0xD68 __ALL___DRM_BUF_STATUS_1_SLICERPL ro — Buffer Status for sliceRPL buffer Valid only in frame decoupled mode. Reflects the current internal and DMA status of the buffer
  fields as __ALL___DRM_BUF_STATUS_1_SLICEINFO
{0xD70+0x10*i} __ALL___DRM_STATUS_BIN{i} ro (i=0..3) — Status of DRM channel controller for bin stream {i} buffer
  fields as __ALL___DRM_STATUS_SLICEINFO
{0xD74+0x10*i} __ALL___DRM_BUF_STATUS_0_BIN{i} ro (i=0..3) — Buffer Status for bin stream {i} buffer Valid only in frame decoupled mode Reflects the current internal and DMA status of bin stream {i} buffer
  [23:16] CUR_ENTRY_IDX — Unused
  [15:8] NUM_VALID_SL2_PAGES — Indicates the number of pages currently valid in SL2. This field indicates the number of pages available for the ECD to read from SL2. This count is initialized to 0 on DRM initialization.This count is incremented on completion of each page of DMA. The count is decremented whenever one page of data is consumed by the ECD core.
  [7:0] CUR_SL2_PAGE_OFFSET — Indicates the SL2 page number where the next data will be read from by the ECD core (MBP); valid values are 0 to DRM_BUF_PARAMS_[BUFFER_NAME].NUM_PAGES - 1; reset on DMA initialization
{0xD78+0x10*i} __ALL___DRM_BUF_STATUS_1_BIN{i} ro (i=0..3) — Buffer Status for bin stream {i} buffer Valid only in frame decoupled mode. Reflects the current internal and DMA status of bin stream {i} buffer
  [21:0] CUR_SL2_ADDR — Indicates the SL2 address of the page where the next data will be read from, by the ECD core (MBP) ; reset on DMA initialization to SL2 base address of the buffer in SL2
{0xD7C+0x10*i} __ALL___DRM_BUF_DMASTATUS_BIN{i} ro (i=0..3) — Buffer DMA Status for bin stream {i} buffer Valid only in frame decoupled mode. Reflects the current DMA status of bin stream {i} buffer
  fields as __ALL___DRM_BUF_DMASTATUS_SLICEINFO
0xDB0 __ALL___DRM_STATUS_COL_MBHDRINFO_TOP ro — Status of DRM channel controller forcolocated top MBHdrInfo buffer
  fields as __ALL___DRM_STATUS_SLICEINFO
0xDB4 __ALL___DRM_BUF_STATUS_0_COL_MBHDRINFO_TOP ro — Buffer Status for colocated top MBHdrInfo buffer Valid only in frame decoupled mode. Reflects the current internal and DMA status of the buffer
  fields as __ALL___DRM_BUF_STATUS_0_SLICEINFO
0xDB8 __ALL___DRM_BUF_STATUS_1_COL_MBHDRINFO_TOP ro — Buffer Status for colocated top MBHdrInfo buffer Valid only in frame decoupled mode. Reflects the current internal and DMA status of the buffer
  fields as __ALL___DRM_BUF_STATUS_1_BIN0
0xDBC __ALL___DRM_BUF_DMASTATUS_COL_MBHDRINFO_TOP ro — Buffer DMA Status for colocated top MBHdrInfo buffer Valid only in frame decoupled mode. Reflects the current DMA status of bin stream 3 buffer
  fields as __ALL___DRM_BUF_DMASTATUS_SLICEINFO
0xDC0 __ALL___DRM_STATUS_COL_MBMVINFO_TOP ro — Status of DRM channel controller forcolocated top MBMVInfo buffer
  fields as __ALL___DRM_STATUS_SLICEINFO
0xDC4 __ALL___DRM_BUF_STATUS_0_COL_MBMVINFO_TOP ro — Buffer Status for colocated top MBMVInfo buffer Valid only in frame decoupled mode. Reflects the current internal and DMA status of the buffer
  fields as __ALL___DRM_BUF_STATUS_0_BIN0
0xDC8 __ALL___DRM_BUF_STATUS_1_COL_MBMVINFO_TOP ro — Buffer Status for colocated top MBMVInfo buffer Valid only in frame decoupled mode. Reflects the current internal and DMA status of the buffer
  fields as __ALL___DRM_BUF_STATUS_1_BIN0
0xDCC __ALL___DRM_BUF_DMASTATUS_COL_MBMVINFO_TOP ro — Buffer DMA Status for colocated top MBMVInfo buffer Valid only in frame decoupled mode. Reflects the current DMA status of bin stream 3 buffer
  fields as __ALL___DRM_BUF_DMASTATUS_SLICEINFO
0xDD0 __ALL___DRM_STATUS_COL_MBHDRINFO_BOT ro — Status of DRM channel controller forcolocated bottom MBHdrInfo buffer
  fields as __ALL___DRM_STATUS_SLICEINFO
0xDD4 __ALL___DRM_BUF_STATUS_0_COL_MBHDRINFO_BOT ro — Buffer Status for colocated bottom MBHdrInfo buffer Valid only in frame decoupled mode. Reflects the current internal and DMA status of the buffer
  fields as __ALL___DRM_BUF_STATUS_0_SLICEINFO
0xDD8 __ALL___DRM_BUF_STATUS_1_COL_MBHDRINFO_BOT ro — Buffer Status for colocated bottom MBHdrInfo buffer Valid only in frame decoupled mode. Reflects the current internal and DMA status of the buffer
  fields as __ALL___DRM_BUF_STATUS_1_BIN0
0xDDC __ALL___DRM_BUF_DMASTATUS_COL_MBHDRINFO_BOT ro — Buffer DMA Status for colocated bottom MBHdrInfo buffer Valid only in frame decoupled mode. Reflects the current DMA status of bin stream 3 buffer
  fields as __ALL___DRM_BUF_DMASTATUS_SLICEINFO
0xDE0 __ALL___DRM_STATUS_COL_MBMVINFO_BOT ro — Status of DRM channel controller forcolocated bottom MBMVInfo buffer
  fields as __ALL___DRM_STATUS_SLICEINFO
0xDE4 __ALL___DRM_BUF_STATUS_0_COL_MBMVINFO_BOT ro — Buffer Status for colocated bottom MBMVInfo buffer Valid only in frame decoupled mode. Reflects the current internal and DMA status of the buffer
  fields as __ALL___DRM_BUF_STATUS_0_BIN0
0xDE8 __ALL___DRM_BUF_STATUS_1_COL_MBMVINFO_BOT ro — Buffer Status for colocated bottom MBMVInfo buffer Valid only in frame decoupled mode. Reflects the current internal and DMA status of the buffer
  fields as __ALL___DRM_BUF_STATUS_1_BIN0
0xDEC __ALL___DRM_BUF_DMASTATUS_COL_MBMVINFO_BOT ro — Buffer DMA Status for colocated bottom MBMVInfo buffer Valid only in frame decoupled mode. Reflects the current DMA status of bin stream 3 buffer
  fields as __ALL___DRM_BUF_DMASTATUS_SLICEINFO
0xDF0 __ALL___DRM_STATUS_MBHDRINFO_TOP ro — Status of DRM channel controller forcurrent top MBHdrInfo buffer
  fields as __ALL___DRM_STATUS_SLICEINFO
0xDF4 __ALL___DRM_BUF_STATUS_0_MBHDRINFO_TOP ro — Buffer Status for current top MBHdrInfo buffer Valid only in frame decoupled mode. Reflects the current internal and DMA status of the buffer
  [23:16] CUR_ENTRY_IDX — For debug only. Indicates the index of the entry that is currently being written or will be written next by the ECD5 core in the current page; reset on DMA initialization
  [15:8] NUM_VALID_SL2_PAGES — Indicates the number of pages currently valid in SL2. This field indicates the number of pages in SL2 available for the ECD core to write into. This count is initialized to the total number of pages (ECD5_BE_BUFFER_CONTROL.DRM_BUF_CFG_[BUFFER_NAME].NUM_PAGES) on DRM initialization. The count is decremented every time ECD writes one page to SL2. The count is incremented whenever the DMA of one page from SL2 to DDR is completed.
  [7:0] CUR_SL2_PAGE_OFFSET — Indicates the SL2 page number where the next data will be written to by the ECD core (MBP); valid values are 0 to DRM_BUF_PARAMS_[BUFFER_NAME].NUM_PAGES - 1; reset on DMA initialization
0xDF8 __ALL___DRM_BUF_STATUS_1_MBHDRINFO_TOP ro — Buffer Status for current top MBHdrInfo buffer Valid only in frame decoupled mode. Reflects the current internal and DMA status of the buffer
  [21:0] CUR_SL2_ADDR — Indicates the SL2 address of the page where the next data will be written to by the ECD core (MBP) ; reset on DMA initialization to SL2 base address of the buffer in SL2
0xDFC __ALL___DRM_BUF_DMASTATUS_MBHDRINFO_TOP ro — Buffer DMA Status for current top MBHdrInfo buffer Valid only in frame decoupled mode. Reflects the current DMA status of bin stream 3 buffer
  [23:16] CUR_SL2_PAGE_OFFSET — Indicates the SL2 page number from which the next page DMA will happen (read from) when enabling conditions for DMA are met (SL2 page is filled by ECD5 core); valid values are 0 to DRM_BUF_PARAMS_[BUFFER_NAME].NUM_PAGES - 1; reset on DMA initialization
  [15:0] TOTAL_PAGES_XFERED — Indicates the total number of pages for which DMA has completed; reset on DMA initialization
